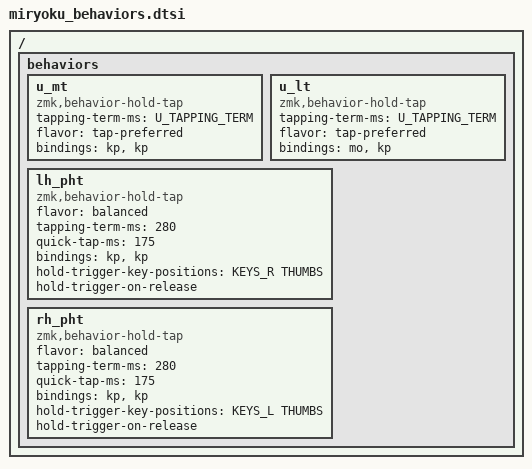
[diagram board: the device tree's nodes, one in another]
// Copyright 2022 Manna Harbour
// https://github.com/manna-harbour/miryoku
#include "mapping/42/corne.h"
/ {
  behaviors {
    u_mt: u_mt {
      compatible = "zmk,behavior-hold-tap";
      #binding-cells = <2>;
      tapping-term-ms = <U_TAPPING_TERM>;
      flavor = "tap-preferred";
      bindings = <&kp>, <&kp>;
    };
    u_lt: u_lt {
      compatible = "zmk,behavior-hold-tap";
      #binding-cells = <2>;
      tapping-term-ms = <U_TAPPING_TERM>;
      flavor = "tap-preferred";
      bindings = <&mo>, <&kp>;
    };
    lh_pht: lh_pht {
            compatible = "zmk,behavior-hold-tap";
            #binding-cells = <2>;
            flavor = "balanced";
            tapping-term-ms = <280>;
            quick-tap-ms = <175>;
            bindings = <&kp>, <&kp>;
            hold-trigger-key-positions = <KEYS_R THUMBS>;
            hold-trigger-on-release;
        };
        rh_pht: rh_pht {
            compatible = "zmk,behavior-hold-tap";
            #binding-cells = <2>;
            flavor = "balanced";
            tapping-term-ms = <280>;
            quick-tap-ms = <175>;
            bindings = <&kp>, <&kp>;
            hold-trigger-key-positions = <KEYS_L THUMBS>;
            hold-trigger-on-release;
        };
  };
};
